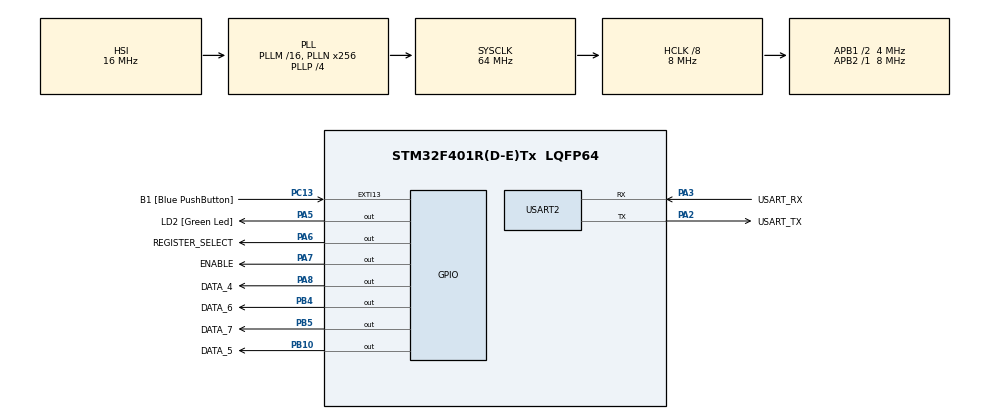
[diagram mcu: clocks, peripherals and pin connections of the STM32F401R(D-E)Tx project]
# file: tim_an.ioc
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Mcu.Family=STM32F4
PA2.GPIO_PuPd=GPIO_NOPULL
RCC.CortexFreq_Value=8000000
PA14.GPIO_Label=TCK
PA3.GPIO_PuPd=GPIO_NOPULL
PA2.GPIO_Speed=GPIO_SPEED_FREQ_LOW
PA6.GPIO_Label=REGISTER_SELECT
PA3.GPIO_Speed=GPIO_SPEED_FREQ_LOW
RCC.SYSCLKSource=RCC_SYSCLKSOURCE_PLLCLK
ProjectManager.StackSize=0x400
TIM1.Prescaler=799
PH0\ -\ OSC_IN.Signal=RCC_OSC_IN
RCC.HCLKFreq_Value=8000000
RCC.APB2TimFreq_Value=8000000
RCC.AHBFreq_Value=8000000
NVIC.EXTI15_10_IRQn=true\:0\:0\:false\:false\:true\:true\:true
RCC.HSE_VALUE=8000000
PC13-ANTI_TAMP.Signal=GPXTI13
PC14-OSC32_IN.Mode=LSE-External-Oscillator
PA14.Mode=Serial_Wire
PA5.GPIO_PuPd=GPIO_NOPULL
PA8.Signal=GPIO_Output
VP_TIM1_VS_ClockSourceINT.Mode=Internal
Mcu.Package=LQFP64
PA6.Signal=GPIO_Output
USART2.VirtualMode=VM_ASYNC
PA2.GPIO_Label=USART_TX
PB5.GPIO_Label=DATA_7
RCC.APB1TimFreq_Value=8000000
TIM1.Period=9999
PB4.Signal=GPIO_Output
PA3.Signal=USART2_RX
PA2.GPIO_Mode=GPIO_MODE_AF_PP
PB3.GPIO_Label=SWO
PC15-OSC32_OUT.Mode=LSE-External-Oscillator
PC13-ANTI_TAMP.GPIO_PuPd=GPIO_NOPULL
PC13-ANTI_TAMP.GPIO_Label=B1 [Blue PushButton]
PH1\ -\ OSC_OUT.Mode=HSE-External-Clock-Source
RCC.APB1CLKDivider=RCC_HCLK_DIV2
PC14-OSC32_IN.Signal=RCC_OSC32_IN
PA13.Signal=SYS_JTMS-SWDIO
PA3.Mode=Asynchronous
PH0\ -\ OSC_IN.Mode=HSE-External-Clock-Source
PA8.GPIO_Label=DATA_4
ProjectManager.TargetToolchain=SW4STM32
PB10.GPIO_Label=DATA_5
PA3.GPIO_Mode=GPIO_MODE_AF_PP
PC15-OSC32_OUT.Signal=RCC_OSC32_OUT
PB10.Signal=GPIO_Output
PA5.Signal=GPIO_Output
PH1\ -\ OSC_OUT.Signal=RCC_OSC_OUT
board=NUCLEO-F401RE
RCC.VCOOutputFreq_Value=256000000
RCC.APB2Freq_Value=8000000
PB4.GPIO_Label=DATA_6
RCC.AHBCLKDivider=RCC_SYSCLK_DIV8
PA13.Mode=Serial_Wire
Mcu.Name=STM32F401R(D-E)Tx
NVIC.TIM1_BRK_TIM9_IRQn=true\:0\:0\:false\:false\:true\:true\:true
PA13.GPIO_Label=TMS
PA2.Signal=USART2_TX
RCC.48MHZClocksFreq_Value=36571428.571428575
PB3.Signal=SYS_JTDO-SWO
RCC.SYSCLKFreq_VALUE=64000000
PB5.Signal=GPIO_Output
PA7.GPIO_Label=ENABLE
PA5.GPIO_Label=LD2 [Green Led]
PC13-ANTI_TAMP.GPIO_ModeDefaultEXTI=GPIO_MODE_IT_FALLING
PA14.Signal=SYS_JTCK-SWCLK
ProjectManager.HeapSize=0x200
NVIC.TIM1_UP_TIM10_IRQn=true\:0\:0\:false\:false\:true\:true\:true
RCC.HSI_VALUE=16000000
RCC.PLLP=RCC_PLLP_DIV4
PA5.GPIO_Speed=GPIO_SPEED_FREQ_LOW
RCC.PLLQ=7
NVIC.PriorityGroup=NVIC_PRIORITYGROUP_0
RCC.PLLN=256
PA2.Mode=Asynchronous
RCC.APB1Freq_Value=4000000
PA5.GPIO_Mode=GPIO_MODE_OUTPUT_PP
PA3.GPIO_Label=USART_RX
PA7.Signal=GPIO_Output

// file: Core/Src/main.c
/* USER CODE BEGIN Header */
/**
  ******************************************************************************
  * @file           : main.c
  * @brief          : Main program body
  ******************************************************************************
  * @attention
  *
  * <h2><center>&copy; Copyright (c) 2020 STMicroelectronics.
  * All rights reserved.</center></h2>
  *
  * This software component is licensed by ST under BSD 3-Clause license,
  * the "License"; You may not use this file except in compliance with the
  * License. You may obtain a copy of the License at:
  *                        opensource.org/licenses/BSD-3-Clause
  *
  ******************************************************************************
  */
/* USER CODE END Header */
#include "main.h"
#include <stdint.h>
#include "lcd.h"

TIM_HandleTypeDef htim1;

UART_HandleTypeDef huart2;

void SystemClock_Config(void);
static void MX_GPIO_Init(void);
static void MX_TIM1_Init(void);
static void MX_USART2_UART_Init(void);

/* USER CODE BEGIN 0 */
static volatile uint8_t interrupt = 0;
extern uint16_t time;
uint16_t time = 0;

/* USER CODE END 0 */

int main(void)
{

  /* MCU Configuration--------------------------------------------------------*/

  /* Reset of all peripherals, Initializes the Flash interface and the Systick. */
  HAL_Init();

  /* Configure the system clock */
  SystemClock_Config();

  /* Initialize all configured peripherals */
  MX_GPIO_Init();
  MX_TIM1_Init();
  MX_USART2_UART_Init();
  /* USER CODE BEGIN 2 */

  GPIO_Port ports[] = {GPIOA, GPIOB, GPIOB, GPIOB};
  GPIO_Pin pins[] = {GPIO_PIN_8, GPIO_PIN_10, GPIO_PIN_4, GPIO_PIN_5};

  DisplayLCD lcd = lcd_generate(ports, pins, GPIOA, GPIO_PIN_6, GPIOA, GPIO_PIN_7);

  lcd_init(&lcd);

  uint8_t state = 1;

  Coordinates pos =  {7,1};

  /* USER CODE END 2 */

  /* Infinite loop */
  while (1)
  {
	if(interrupt) {
		if (state) {
		  state = 0;
	      time = 0;
		  HAL_TIM_Base_Start(&htim1);
		  HAL_TIM_Base_Start_IT(&htim1);
		} else {
		  state = 1;
		  lcd_clear_display(&lcd);
		  lcd_write_data(&lcd,"Elapsed time... ");
		  lcd_pos_cursor(&lcd,pos);
		  lcd_write_int(&lcd,time>>1);
		  lcd_write_data(&lcd," seconds");
		  HAL_TIM_Base_Stop(&htim1);
		  HAL_TIM_Base_Stop_IT(&htim1);
		}
		interrupt = 0;
	}

  }
}

void SystemClock_Config(void)
{
  RCC_OscInitTypeDef RCC_OscInitStruct = {0};
  RCC_ClkInitTypeDef RCC_ClkInitStruct = {0};

  /** Configure the main internal regulator output voltage
  */
  __HAL_RCC_PWR_CLK_ENABLE();
  __HAL_PWR_VOLTAGESCALING_CONFIG(PWR_REGULATOR_VOLTAGE_SCALE2);
  /** Initializes the RCC Oscillators according to the specified parameters
  * in the RCC_OscInitTypeDef structure.
  */
  RCC_OscInitStruct.OscillatorType = RCC_OSCILLATORTYPE_HSI;
  RCC_OscInitStruct.HSIState = RCC_HSI_ON;
  RCC_OscInitStruct.HSICalibrationValue = RCC_HSICALIBRATION_DEFAULT;
  RCC_OscInitStruct.PLL.PLLState = RCC_PLL_ON;
  RCC_OscInitStruct.PLL.PLLSource = RCC_PLLSOURCE_HSI;
  RCC_OscInitStruct.PLL.PLLM = 16;
  RCC_OscInitStruct.PLL.PLLN = 256;
  RCC_OscInitStruct.PLL.PLLP = RCC_PLLP_DIV4;
  RCC_OscInitStruct.PLL.PLLQ = 7;
  if (HAL_RCC_OscConfig(&RCC_OscInitStruct) != HAL_OK)
  {
    Error_Handler();
  }
  /** Initializes the CPU, AHB and APB buses clocks
  */
  RCC_ClkInitStruct.ClockType = RCC_CLOCKTYPE_HCLK|RCC_CLOCKTYPE_SYSCLK
                              |RCC_CLOCKTYPE_PCLK1|RCC_CLOCKTYPE_PCLK2;
  RCC_ClkInitStruct.SYSCLKSource = RCC_SYSCLKSOURCE_PLLCLK;
  RCC_ClkInitStruct.AHBCLKDivider = RCC_SYSCLK_DIV8;
  RCC_ClkInitStruct.APB1CLKDivider = RCC_HCLK_DIV2;
  RCC_ClkInitStruct.APB2CLKDivider = RCC_HCLK_DIV1;

  if (HAL_RCC_ClockConfig(&RCC_ClkInitStruct, FLASH_LATENCY_0) != HAL_OK)
  {
    Error_Handler();
  }
}

static void MX_TIM1_Init(void)
{

  TIM_ClockConfigTypeDef sClockSourceConfig = {0};
  TIM_MasterConfigTypeDef sMasterConfig = {0};

  htim1.Instance = TIM1;
  htim1.Init.Prescaler = 399;
  htim1.Init.CounterMode = TIM_COUNTERMODE_UP;
  htim1.Init.Period = 9999;
  htim1.Init.ClockDivision = TIM_CLOCKDIVISION_DIV1;
  htim1.Init.RepetitionCounter = 0;
  htim1.Init.AutoReloadPreload = TIM_AUTORELOAD_PRELOAD_DISABLE;
  if (HAL_TIM_Base_Init(&htim1) != HAL_OK)
  {
    Error_Handler();
  }
  sClockSourceConfig.ClockSource = TIM_CLOCKSOURCE_INTERNAL;
  if (HAL_TIM_ConfigClockSource(&htim1, &sClockSourceConfig) != HAL_OK)
  {
    Error_Handler();
  }
  sMasterConfig.MasterOutputTrigger = TIM_TRGO_RESET;
  sMasterConfig.MasterSlaveMode = TIM_MASTERSLAVEMODE_DISABLE;
  if (HAL_TIMEx_MasterConfigSynchronization(&htim1, &sMasterConfig) != HAL_OK)
  {
    Error_Handler();
  }

}

static void MX_USART2_UART_Init(void)
{

  huart2.Instance = USART2;
  huart2.Init.BaudRate = 115200;
  huart2.Init.WordLength = UART_WORDLENGTH_8B;
  huart2.Init.StopBits = UART_STOPBITS_1;
  huart2.Init.Parity = UART_PARITY_NONE;
  huart2.Init.Mode = UART_MODE_TX_RX;
  huart2.Init.HwFlowCtl = UART_HWCONTROL_NONE;
  huart2.Init.OverSampling = UART_OVERSAMPLING_16;
  if (HAL_UART_Init(&huart2) != HAL_OK)
  {
    Error_Handler();
  }

}

static void MX_GPIO_Init(void)
{
  GPIO_InitTypeDef GPIO_InitStruct = {0};

  /* GPIO Ports Clock Enable */
  __HAL_RCC_GPIOC_CLK_ENABLE();
  __HAL_RCC_GPIOH_CLK_ENABLE();
  __HAL_RCC_GPIOA_CLK_ENABLE();
  __HAL_RCC_GPIOB_CLK_ENABLE();

  /*Configure GPIO pin Output Level */
  HAL_GPIO_WritePin(GPIOA, LD2_Pin|REGISTER_SELECT_Pin|ENABLE_Pin|DATA_4_Pin, GPIO_PIN_RESET);

  /*Configure GPIO pin Output Level */
  HAL_GPIO_WritePin(GPIOB, DATA_5_Pin|DATA_6_Pin|DATA_7_Pin, GPIO_PIN_RESET);

  /*Configure GPIO pin : B1_Pin */
  GPIO_InitStruct.Pin = B1_Pin;
  GPIO_InitStruct.Mode = GPIO_MODE_IT_FALLING;
  GPIO_InitStruct.Pull = GPIO_NOPULL;
  HAL_GPIO_Init(B1_GPIO_Port, &GPIO_InitStruct);

  /*Configure GPIO pins : LD2_Pin REGISTER_SELECT_Pin ENABLE_Pin DATA_4_Pin */
  GPIO_InitStruct.Pin = LD2_Pin|REGISTER_SELECT_Pin|ENABLE_Pin|DATA_4_Pin;
  GPIO_InitStruct.Mode = GPIO_MODE_OUTPUT_PP;
  GPIO_InitStruct.Pull = GPIO_NOPULL;
  GPIO_InitStruct.Speed = GPIO_SPEED_FREQ_LOW;
  HAL_GPIO_Init(GPIOA, &GPIO_InitStruct);

  /*Configure GPIO pins : DATA_5_Pin DATA_6_Pin DATA_7_Pin */
  GPIO_InitStruct.Pin = DATA_5_Pin|DATA_6_Pin|DATA_7_Pin;
  GPIO_InitStruct.Mode = GPIO_MODE_OUTPUT_PP;
  GPIO_InitStruct.Pull = GPIO_NOPULL;
  GPIO_InitStruct.Speed = GPIO_SPEED_FREQ_LOW;
  HAL_GPIO_Init(GPIOB, &GPIO_InitStruct);

  /* EXTI interrupt init*/
  HAL_NVIC_SetPriority(EXTI15_10_IRQn, 0, 0);
  HAL_NVIC_EnableIRQ(EXTI15_10_IRQn);

}

/* USER CODE BEGIN 4 */
void HAL_GPIO_EXTI_Callback(uint16_t GPIO_Pin) {
	if(GPIO_Pin==GPIO_PIN_13) {
		interrupt = 1;
	}
}

/* USER CODE END 4 */

void Error_Handler(void)
{
}

/************************ (C) COPYRIGHT STMicroelectronics *****END OF FILE****/
